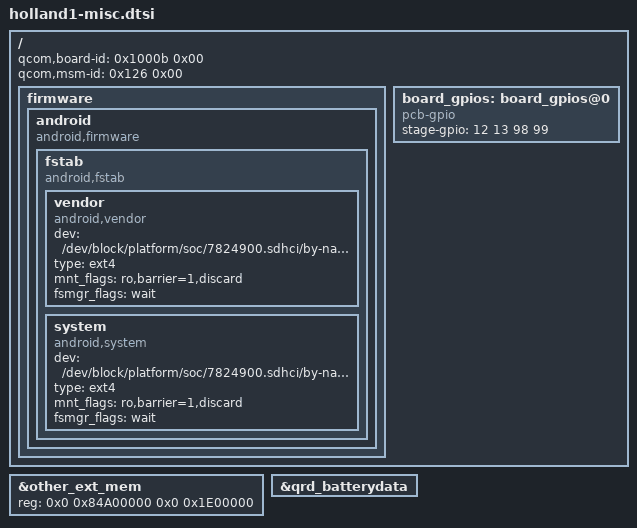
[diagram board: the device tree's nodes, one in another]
/* Copyright (c) 2020, The Linux Foundation. All rights reserved.
*  Copyright (c) 2020, Jebaitedneko.
*
* This program is free software; you can redistribute it and/or modify
* it under the terms of the GNU General Public License version 2 and
* only version 2 as published by the Free Software Foundation.
*
* This program is distributed in the hope that it will be useful,
* but WITHOUT ANY WARRANTY; without even the implied warranty of
* MERCHANTABILITY or FITNESS FOR A PARTICULAR PURPOSE.  See the
* GNU General Public License for more details.
*/

/ {

	qcom,board-id = <0x1000b 0x00>;
	qcom,msm-id = <0x126 0x00>;

	firmware {

		android {

			compatible = "android,firmware";

			fstab {
				compatible = "android,fstab";

				vendor {

					compatible = "android,vendor";
					dev = "/dev/block/platform/soc/7824900.sdhci/by-name/vendor";
					type = "ext4";
					mnt_flags = "ro,barrier=1,discard";
					fsmgr_flags = "wait";
					status = "ok";
				};

				system {

					compatible = "android,system";
					dev = "/dev/block/platform/soc/7824900.sdhci/by-name/system";
					type = "ext4";
					mnt_flags = "ro,barrier=1,discard";
					fsmgr_flags = "wait";
					status = "ok";
				};
			};

			/delete-node/ vbmeta;
		};
	};

	board_gpios: board_gpios@0 {

		compatible = "pcb-gpio";
		stage-gpio = <12 13 98 99>;
	};
};

&other_ext_mem {
	reg = <0x0 0x84A00000 0x0 0x1E00000>;
};

&qrd_batterydata {
	#include "batterydata_Amazon_4V4_4000mAh.dtsi"
	/delete-node/ qcom,qrd_msm8937_sku2_2590mah;
};
